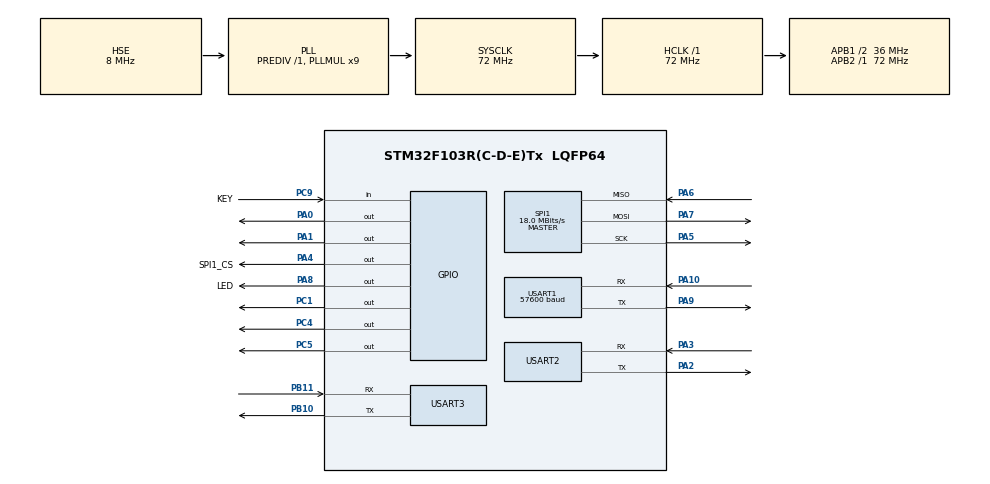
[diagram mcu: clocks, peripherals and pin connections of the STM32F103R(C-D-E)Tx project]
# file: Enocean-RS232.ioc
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Dma.Request0=USART3_TX
Dma.Request1=USART2_TX
Dma.Request2=USART2_RX
Dma.Request3=USART1_TX
Dma.Request4=USART1_RX
Dma.USART1_RX.4.Direction=DMA_PERIPH_TO_MEMORY
Dma.USART1_RX.4.Instance=DMA1_Channel5
Dma.USART1_RX.4.MemDataAlignment=DMA_MDATAALIGN_BYTE
Dma.USART1_RX.4.MemInc=DMA_MINC_ENABLE
Dma.USART1_RX.4.Mode=DMA_NORMAL
Dma.USART1_RX.4.PeriphDataAlignment=DMA_PDATAALIGN_BYTE
Dma.USART1_RX.4.PeriphInc=DMA_PINC_DISABLE
Dma.USART1_RX.4.Priority=DMA_PRIORITY_HIGH
Dma.USART1_TX.3.Direction=DMA_MEMORY_TO_PERIPH
Dma.USART1_TX.3.Instance=DMA1_Channel4
Dma.USART1_TX.3.MemDataAlignment=DMA_MDATAALIGN_BYTE
Dma.USART1_TX.3.MemInc=DMA_MINC_ENABLE
Dma.USART1_TX.3.Mode=DMA_NORMAL
Dma.USART1_TX.3.PeriphDataAlignment=DMA_PDATAALIGN_BYTE
Dma.USART1_TX.3.PeriphInc=DMA_PINC_DISABLE
Dma.USART1_TX.3.Priority=DMA_PRIORITY_HIGH
Dma.USART2_RX.2.Direction=DMA_PERIPH_TO_MEMORY
Dma.USART2_RX.2.Instance=DMA1_Channel6
Dma.USART2_RX.2.MemDataAlignment=DMA_MDATAALIGN_BYTE
Dma.USART2_RX.2.MemInc=DMA_MINC_ENABLE
Dma.USART2_RX.2.Mode=DMA_NORMAL
Dma.USART2_RX.2.PeriphDataAlignment=DMA_PDATAALIGN_BYTE
Dma.USART2_RX.2.PeriphInc=DMA_PINC_DISABLE
Dma.USART2_RX.2.Priority=DMA_PRIORITY_HIGH
Dma.USART2_TX.1.Direction=DMA_MEMORY_TO_PERIPH
Dma.USART2_TX.1.Instance=DMA1_Channel7
Dma.USART2_TX.1.MemDataAlignment=DMA_MDATAALIGN_BYTE
Dma.USART2_TX.1.MemInc=DMA_MINC_ENABLE
Dma.USART2_TX.1.Mode=DMA_NORMAL
Dma.USART2_TX.1.PeriphDataAlignment=DMA_PDATAALIGN_BYTE
Dma.USART2_TX.1.PeriphInc=DMA_PINC_DISABLE
Dma.USART2_TX.1.Priority=DMA_PRIORITY_HIGH
Dma.USART3_TX.0.Direction=DMA_MEMORY_TO_PERIPH
Dma.USART3_TX.0.Instance=DMA1_Channel2
Dma.USART3_TX.0.MemDataAlignment=DMA_MDATAALIGN_BYTE
Dma.USART3_TX.0.MemInc=DMA_MINC_ENABLE
Dma.USART3_TX.0.Mode=DMA_NORMAL
Dma.USART3_TX.0.PeriphDataAlignment=DMA_PDATAALIGN_BYTE
Dma.USART3_TX.0.PeriphInc=DMA_PINC_DISABLE
Dma.USART3_TX.0.Priority=DMA_PRIORITY_HIGH
FREERTOS.INCLUDE_pcTaskGetTaskName=1
FREERTOS.INCLUDE_uxTaskGetStackHighWaterMark=1
FREERTOS.INCLUDE_xTaskGetCurrentTaskHandle=1
FREERTOS.Queues01=serial_queue,8,uint32_t,NULL;flash_queue,5,uint32_t,NULL;tcm300_tx_queue,8,uint32_t,NULL
FREERTOS.Tasks01=sys_watcher,0,200,sys_watcher_function,Default;flash_server,1,600,flash_server_function,Default;serial_server,2,400,serial_server_function,Default;sys_core,1,300,sys_core_function,Default;tcm300_server,2,300,tcm300_tx_server,Default;web_server,1,300,web_server_function,Default
FREERTOS.configTOTAL_HEAP_SIZE=20480
FREERTOS.configUSE_IDLE_HOOK=1
FREERTOS.configUSE_MUTEXES=1
FREERTOS.configUSE_RECURSIVE_MUTEXES=1
FREERTOS.configUSE_TICK_HOOK=1
FREERTOS.configUSE_TIMERS=1
Mcu.Family=STM32F1
Mcu.Name=STM32F103R(C-D-E)Tx
Mcu.Package=LQFP64
NVIC.DMA1_Channel2_IRQn=true\:5\:0\:false\:false\:true\:true
NVIC.DMA1_Channel4_IRQn=true\:5\:0\:false\:false\:true\:true
NVIC.DMA1_Channel5_IRQn=true\:5\:0\:false\:false\:true\:true
NVIC.DMA1_Channel6_IRQn=true\:5\:0\:false\:false\:true\:true
NVIC.DMA1_Channel7_IRQn=true\:5\:0\:false\:false\:true\:true
NVIC.PriorityGroup=NVIC_PRIORITYGROUP_4
NVIC.SPI1_IRQn=true\:6\:0\:true\:false\:true\:false
NVIC.TIM1_UP_IRQn=true\:0\:0\:false\:false\:true\:false
NVIC.TIM2_IRQn=true\:5\:0\:true\:false\:true\:false
NVIC.TimeBase=TIM1_UP_IRQn
NVIC.TimeBaseIP=TIM1
NVIC.USART1_IRQn=true\:5\:0\:true\:false\:true\:true
NVIC.USART2_IRQn=true\:5\:0\:true\:false\:true\:true
NVIC.USART3_IRQn=true\:5\:0\:true\:false\:true\:true
PA0-WKUP.Signal=GPIO_Output
PA1.Signal=GPIO_Output
PA10.GPIO_PuPd=GPIO_NOPULL
PA10.Mode=Asynchronous
PA10.Signal=USART1_RX
PA13.Mode=Serial_Wire
PA13.Signal=SYS_JTMS-SWDIO
PA14.Mode=Serial_Wire
PA14.Signal=SYS_JTCK-SWCLK
PA2.Mode=Asynchronous
PA2.Signal=USART2_TX
PA3.GPIO_PuPd=GPIO_NOPULL
PA3.Mode=Asynchronous
PA3.Signal=USART2_RX
PA4.GPIO_Label=SPI1_CS
PA4.Signal=GPIO_Output
PA5.Mode=Full_Duplex_Master
PA5.Signal=SPI1_SCK
PA6.Mode=Full_Duplex_Master
PA6.Signal=SPI1_MISO
PA7.Mode=Full_Duplex_Master
PA7.Signal=SPI1_MOSI
PA8.GPIO_Label=LED
PA8.Signal=GPIO_Output
PA9.Mode=Asynchronous
PA9.Signal=USART1_TX
PB10.Mode=Asynchronous
PB10.Signal=USART3_TX
PB11.GPIO_PuPd=GPIO_NOPULL
PB11.Mode=Asynchronous
PB11.Signal=USART3_RX
PC1.Signal=GPIO_Output
PC4.Signal=GPIO_Output
PC5.Signal=GPIO_Output
PC9.GPIO_Label=KEY
PC9.Signal=GPIO_Input
PD0-OSC_IN.Mode=HSE-External-Oscillator
PD0-OSC_IN.Signal=RCC_OSC_IN
PD1-OSC_OUT.Mode=HSE-External-Oscillator
PD1-OSC_OUT.Signal=RCC_OSC_OUT
ProjectManager.HeapSize=0x2000
ProjectManager.StackSize=0xA00
ProjectManager.TargetToolchain=MDK-ARM V5
RCC.AHBFreq_Value=72000000
RCC.APB1CLKDivider=RCC_HCLK_DIV2
RCC.APB1Freq_Value=36000000
RCC.APB1TimFreq_Value=72000000
RCC.APB2Freq_Value=72000000
RCC.APB2TimFreq_Value=72000000
RCC.HCLKFreq_Value=72000000
RCC.HSIState=RCC_HSI_ON
RCC.PLLMUL=RCC_PLL_MUL9
RCC.PLLSourceVirtual=RCC_PLLSOURCE_HSE
RCC.SYSCLKFreq_VALUE=72000000
RCC.SYSCLKSource=RCC_SYSCLKSOURCE_PLLCLK
RCC.USBFreq_Value=72000000
SPI1.BaudRatePrescaler=SPI_BAUDRATEPRESCALER_4
SPI1.CLKPolarity=SPI_POLARITY_LOW
SPI1.CalculateBaudRate=18.0 MBits/s
SPI1.Mode=SPI_MODE_MASTER
TIM2.Period=1000-1
TIM2.Prescaler=72-1
TIM4.Period=2999
TIM4.Prescaler=23
USART1.BaudRate=57600
VP_FREERTOS_VS_ENABLE.Mode=Enabled
VP_SYS_VS_tim1.Mode=TIM1
VP_TIM2_VS_ClockSourceINT.Mode=Internal
VP_TIM4_VS_ClockSourceINT.Mode=Internal
board=Enocean-RS232

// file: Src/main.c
/**
  ******************************************************************************
  * File Name          : main.c
  * Description        : Main program body
  ******************************************************************************
  *
  * COPYRIGHT(c) 2018 STMicroelectronics
  *
  * Redistribution and use in source and binary forms, with or without modification,
  * are permitted provided that the following conditions are met:
  *   1. Redistributions of source code must retain the above copyright notice,
  *      this list of conditions and the following disclaimer.
  *   2. Redistributions in binary form must reproduce the above copyright notice,
  *      this list of conditions and the following disclaimer in the documentation
  *      and/or other materials provided with the distribution.
  *   3. Neither the name of STMicroelectronics nor the names of its contributors
  *      may be used to endorse or promote products derived from this software
  *      without specific prior written permission.
  *
  * THIS SOFTWARE IS PROVIDED BY THE COPYRIGHT HOLDERS AND CONTRIBUTORS "AS IS"
  * AND ANY EXPRESS OR IMPLIED WARRANTIES, INCLUDING, BUT NOT LIMITED TO, THE
  * IMPLIED WARRANTIES OF MERCHANTABILITY AND FITNESS FOR A PARTICULAR PURPOSE ARE
  * DISCLAIMED. IN NO EVENT SHALL THE COPYRIGHT HOLDER OR CONTRIBUTORS BE LIABLE
  * FOR ANY DIRECT, INDIRECT, INCIDENTAL, SPECIAL, EXEMPLARY, OR CONSEQUENTIAL
  * DAMAGES (INCLUDING, BUT NOT LIMITED TO, PROCUREMENT OF SUBSTITUTE GOODS OR
  * SERVICES; LOSS OF USE, DATA, OR PROFITS; OR BUSINESS INTERRUPTION) HOWEVER
  * CAUSED AND ON ANY THEORY OF LIABILITY, WHETHER IN CONTRACT, STRICT LIABILITY,
  * OR TORT (INCLUDING NEGLIGENCE OR OTHERWISE) ARISING IN ANY WAY OUT OF THE USE
  * OF THIS SOFTWARE, EVEN IF ADVISED OF THE POSSIBILITY OF SUCH DAMAGE.
  *
  ******************************************************************************
  */
#include "stm32f1xx_hal.h"
#include "cmsis_os.h"
#include "dma.h"
#include "spi.h"
#include "tim.h"
#include "usart.h"
#include "gpio.h"

/* USER CODE BEGIN PV */
/* Private variables ---------------------------------------------------------*/

/* USER CODE END PV */

void SystemClock_Config(void);
void Error_Handler(void);
void MX_FREERTOS_Init(void);

/* USER CODE BEGIN PFP */
/* Private function prototypes -----------------------------------------------*/

/* USER CODE END PFP */

int main(void)
{

  /* MCU Configuration----------------------------------------------------------*/

  /* Reset of all peripherals, Initializes the Flash interface and the Systick. */
  HAL_Init();

  /* Configure the system clock */
  SystemClock_Config();

  /* Initialize all configured peripherals */
  MX_GPIO_Init();
  MX_DMA_Init();
  MX_SPI1_Init();
  MX_TIM2_Init();
  MX_USART1_UART_Init();
  MX_USART2_UART_Init();
  MX_USART3_UART_Init();
  MX_TIM4_Init();

  /* Call init function for freertos objects (in freertos.c) */
  MX_FREERTOS_Init();

  /* Start scheduler */
  osKernelStart();

  /* We should never get here as control is now taken by the scheduler */

  /* Infinite loop */
  while (1)
  {

  }

}

/** System Clock Configuration
*/
void SystemClock_Config(void)
{

  RCC_OscInitTypeDef RCC_OscInitStruct;
  RCC_ClkInitTypeDef RCC_ClkInitStruct;

  RCC_OscInitStruct.OscillatorType = RCC_OSCILLATORTYPE_HSE;
  RCC_OscInitStruct.HSEState = RCC_HSE_ON;
  RCC_OscInitStruct.HSEPredivValue = RCC_HSE_PREDIV_DIV1;
  RCC_OscInitStruct.PLL.PLLState = RCC_PLL_ON;
  RCC_OscInitStruct.PLL.PLLSource = RCC_PLLSOURCE_HSE;
  RCC_OscInitStruct.PLL.PLLMUL = RCC_PLL_MUL9;
  if (HAL_RCC_OscConfig(&RCC_OscInitStruct) != HAL_OK)
  {
    Error_Handler();
  }

  RCC_ClkInitStruct.ClockType = RCC_CLOCKTYPE_HCLK|RCC_CLOCKTYPE_SYSCLK
                              |RCC_CLOCKTYPE_PCLK1|RCC_CLOCKTYPE_PCLK2;
  RCC_ClkInitStruct.SYSCLKSource = RCC_SYSCLKSOURCE_PLLCLK;
  RCC_ClkInitStruct.AHBCLKDivider = RCC_SYSCLK_DIV1;
  RCC_ClkInitStruct.APB1CLKDivider = RCC_HCLK_DIV2;
  RCC_ClkInitStruct.APB2CLKDivider = RCC_HCLK_DIV1;
  if (HAL_RCC_ClockConfig(&RCC_ClkInitStruct, FLASH_LATENCY_2) != HAL_OK)
  {
    Error_Handler();
  }

  HAL_SYSTICK_Config(HAL_RCC_GetHCLKFreq()/1000);

  HAL_SYSTICK_CLKSourceConfig(SYSTICK_CLKSOURCE_HCLK);

  /* SysTick_IRQn interrupt configuration */
  HAL_NVIC_SetPriority(SysTick_IRQn, 15, 0);
}

void HAL_TIM_PeriodElapsedCallback(TIM_HandleTypeDef *htim)
{
  if (htim->Instance == TIM1) {
    HAL_IncTick();
  }
}

void Error_Handler(void)
{
  while(1)
  {
  }
}

/************************ (C) COPYRIGHT STMicroelectronics *****END OF FILE****/

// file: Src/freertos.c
/**
  ******************************************************************************
  * File Name          : freertos.c
  * Description        : Code for freertos applications
  ******************************************************************************
  *
  * COPYRIGHT(c) 2018 STMicroelectronics
  *
  * Redistribution and use in source and binary forms, with or without modification,
  * are permitted provided that the following conditions are met:
  *   1. Redistributions of source code must retain the above copyright notice,
  *      this list of conditions and the following disclaimer.
  *   2. Redistributions in binary form must reproduce the above copyright notice,
  *      this list of conditions and the following disclaimer in the documentation
  *      and/or other materials provided with the distribution.
  *   3. Neither the name of STMicroelectronics nor the names of its contributors
  *      may be used to endorse or promote products derived from this software
  *      without specific prior written permission.
  *
  * THIS SOFTWARE IS PROVIDED BY THE COPYRIGHT HOLDERS AND CONTRIBUTORS "AS IS"
  * AND ANY EXPRESS OR IMPLIED WARRANTIES, INCLUDING, BUT NOT LIMITED TO, THE
  * IMPLIED WARRANTIES OF MERCHANTABILITY AND FITNESS FOR A PARTICULAR PURPOSE ARE
  * DISCLAIMED. IN NO EVENT SHALL THE COPYRIGHT HOLDER OR CONTRIBUTORS BE LIABLE
  * FOR ANY DIRECT, INDIRECT, INCIDENTAL, SPECIAL, EXEMPLARY, OR CONSEQUENTIAL
  * DAMAGES (INCLUDING, BUT NOT LIMITED TO, PROCUREMENT OF SUBSTITUTE GOODS OR
  * SERVICES; LOSS OF USE, DATA, OR PROFITS; OR BUSINESS INTERRUPTION) HOWEVER
  * CAUSED AND ON ANY THEORY OF LIABILITY, WHETHER IN CONTRACT, STRICT LIABILITY,
  * OR TORT (INCLUDING NEGLIGENCE OR OTHERWISE) ARISING IN ANY WAY OUT OF THE USE
  * OF THIS SOFTWARE, EVEN IF ADVISED OF THE POSSIBILITY OF SUCH DAMAGE.
  *
  ******************************************************************************
  */

#include "FreeRTOS.h"
#include "task.h"
#include "cmsis_os.h"

osThreadId sys_watcherHandle;
osThreadId flash_serverHandle;
osThreadId serial_serverHandle;
osThreadId sys_coreHandle;
osThreadId tcm300_serverHandle;
osThreadId web_serverHandle;
osMessageQId serial_queueHandle;
osMessageQId flash_queueHandle;
osMessageQId tcm300_tx_queueHandle;

void sys_watcher_function(void const * argument);
void flash_server_function(void const * argument);
void serial_server_function(void const * argument);
void sys_core_function(void const * argument);
void tcm300_tx_server(void const * argument);
void web_server_function(void const * argument);

void MX_FREERTOS_Init(void); /* (MISRA C 2004 rule 8.1) */

/* Hook prototypes */
void vApplicationIdleHook(void);
void vApplicationTickHook(void);

/* Init FreeRTOS */

void MX_FREERTOS_Init(void) {

  /* Create the thread(s) */
  /* definition and creation of sys_watcher */
  osThreadDef(sys_watcher, sys_watcher_function, osPriorityNormal, 0, 200);
  sys_watcherHandle = osThreadCreate(osThread(sys_watcher), NULL);

  /* definition and creation of flash_server */
  osThreadDef(flash_server, flash_server_function, osPriorityAboveNormal, 0, 600);
  flash_serverHandle = osThreadCreate(osThread(flash_server), NULL);

  /* definition and creation of serial_server */
  osThreadDef(serial_server, serial_server_function, osPriorityHigh, 0, 400);
  serial_serverHandle = osThreadCreate(osThread(serial_server), NULL);

  /* definition and creation of sys_core */
  osThreadDef(sys_core, sys_core_function, osPriorityAboveNormal, 0, 300);
  sys_coreHandle = osThreadCreate(osThread(sys_core), NULL);

  /* definition and creation of tcm300_server */
  osThreadDef(tcm300_server, tcm300_tx_server, osPriorityHigh, 0, 300);
  tcm300_serverHandle = osThreadCreate(osThread(tcm300_server), NULL);

  /* definition and creation of web_server */
  osThreadDef(web_server, web_server_function, osPriorityAboveNormal, 0, 300);
  web_serverHandle = osThreadCreate(osThread(web_server), NULL);

  /* Create the queue(s) */
  /* definition and creation of serial_queue */
  osMessageQDef(serial_queue, 8, uint32_t);
  serial_queueHandle = osMessageCreate(osMessageQ(serial_queue), NULL);

  /* definition and creation of flash_queue */
  osMessageQDef(flash_queue, 5, uint32_t);
  flash_queueHandle = osMessageCreate(osMessageQ(flash_queue), NULL);

  /* definition and creation of tcm300_tx_queue */
  osMessageQDef(tcm300_tx_queue, 8, uint32_t);
  tcm300_tx_queueHandle = osMessageCreate(osMessageQ(tcm300_tx_queue), NULL);

}

/* sys_watcher_function function */
void sys_watcher_function(void const * argument)
{

  /* USER CODE BEGIN sys_watcher_function */
  InitW5500();
  osDelay(1000);
  vStartMQTTTasks(400,osPriorityAboveNormal);
  /* Infinite loop */
  for(;;)
  {
    osDelay(1);
  }
  /* USER CODE END sys_watcher_function */
}

/* flash_server_function function */
void flash_server_function(void const * argument)
{
  for(;;)
  {
    osDelay(1);
  }
}

/* serial_server_function function */
void serial_server_function(void const * argument)
{
  for(;;)
  {
    osDelay(1);
  }
}

/* sys_core_function function */
void sys_core_function(void const * argument)
{
  for(;;)
  {
    osDelay(1);
  }
}

/* tcm300_tx_server function */
void tcm300_tx_server(void const * argument)
{
  for(;;)
  {
    osDelay(1);
  }
}

/* web_server_function function */
void web_server_function(void const * argument)
{
  for(;;)
  {
    osDelay(1);
  }
}

/************************ (C) COPYRIGHT STMicroelectronics *****END OF FILE****/
